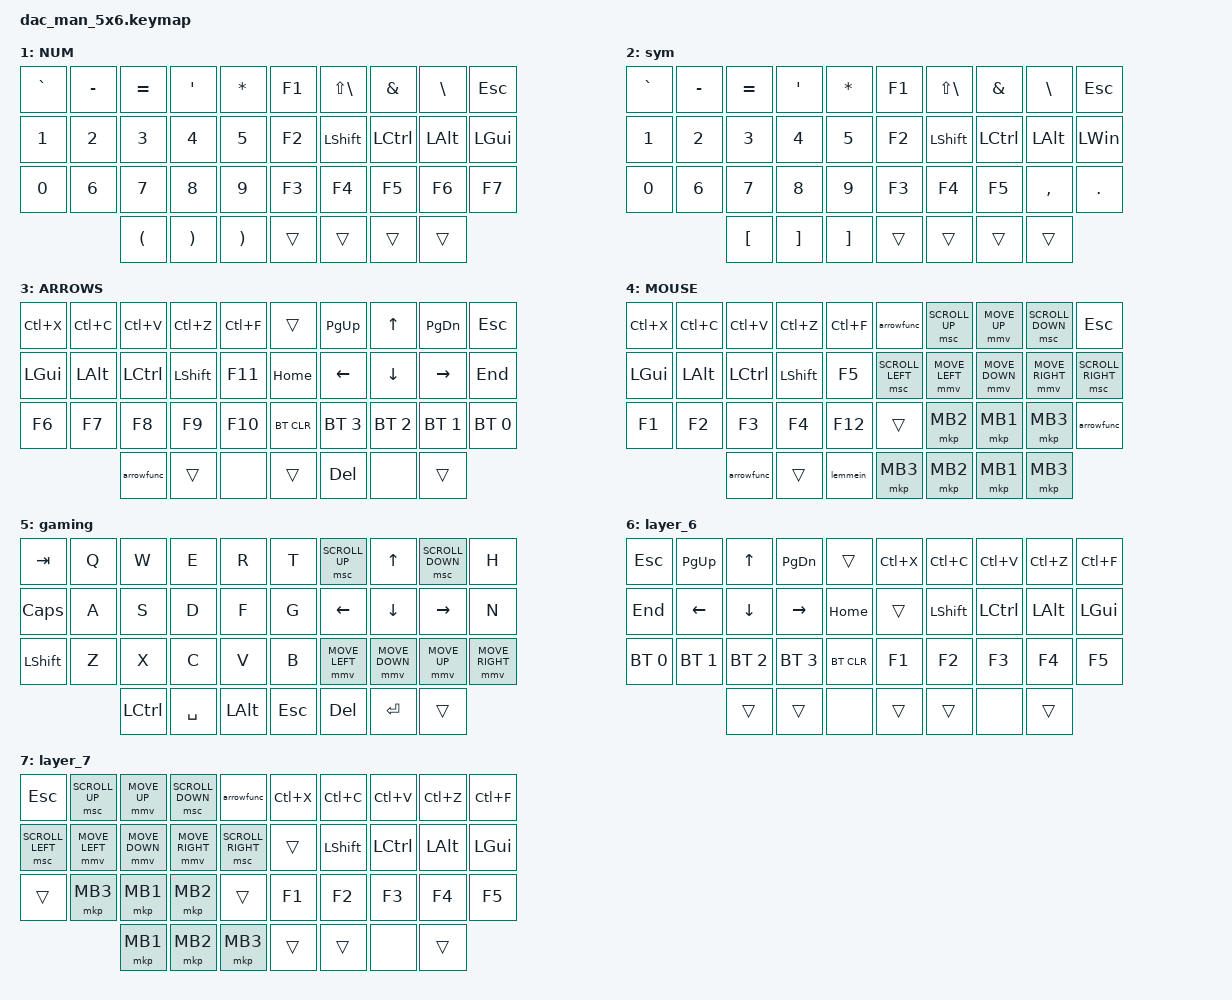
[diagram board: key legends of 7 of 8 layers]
#include <behaviors.dtsi>
#include <dt-bindings/zmk/mouse.h>
#include "mouse.dtsi"
#include <dt-bindings/zmk/bt.h>
#include <dt-bindings/zmk/keys.h>

/ {
    behaviors {
        new_behavior: new_behavior {
            compatible = "zmk,behavior-sensor-rotate";
            label = "NEW_BEHAVIOR";
            #sensor-binding-cells = <0>;
            bindings = <&msc SCROLL_DOWN>, <&msc SCROLL_UP>;
        };
    };

    combos {
        compatible = "zmk,combos";

        hotalt {
            bindings = <&mo 4>;
            key-positions = <34 35>;
        };

        hotctrl {
            bindings = <&mo 3>;
            key-positions = <33 34>;
        };

        gaming {
            bindings = <&tog 5>;
            key-positions = <33 32>;
        };

        qshift {
            bindings = <&mo 6>;
            key-positions = <32 31>;
        };

        qesc {
            bindings = <&mo 7>;
            key-positions = <31 30>;
        };

        space {
            bindings = <&kp SPACE>;
            key-positions = <11 12>;
        };

        esc {
            bindings = <&kp ESC>;
            key-positions = <1 2>;
        };

        tab {
            bindings = <&kp TAB>;
            key-positions = <22 21>;
        };

        bspace {
            bindings = <&kp BACKSPACE>;
            key-positions = <17 18>;
        };

        enter {
            bindings = <&kp ENTER>;
            key-positions = <27 28>;
        };

        del {
            bindings = <&kp DEL>;
            key-positions = <7 8>;
        };

        Lshift-0 {
            bindings = <&kp LEFT_SHIFT>;
            key-positions = <30 13>;
        };

        Lshift-1 {
            bindings = <&kp LEFT_SHIFT>;
            key-positions = <31 13>;
        };

        Rshift-0 {
            bindings = <&kp LEFT_SHIFT>;
            key-positions = <16 35>;
        };

        Rshift-1 {
            bindings = <&kp LEFT_SHIFT>;
            key-positions = <34 16>;
        };

        Lctrl_0 {
            bindings = <&kp LCTRL>;
            key-positions = <30 12>;
        };

        Lctrl_1 {
            bindings = <&kp LCTRL>;
            key-positions = <31 12>;
        };

        Rctrl_0 {
            bindings = <&kp LCTRL>;
            key-positions = <17 35>;
        };

        Rctrl_1 {
            bindings = <&kp LCTRL>;
            key-positions = <17 34>;
        };

        Lalt_0 {
            bindings = <&kp LEFT_ALT>;
            key-positions = <30 11>;
        };

        Lalt_1 {
            bindings = <&kp LEFT_ALT>;
            key-positions = <11 31>;
        };

        Ralt_0 {
            bindings = <&kp LEFT_ALT>;
            key-positions = <35 18>;
        };

        Ralt_1 {
            bindings = <&kp LEFT_ALT>;
            key-positions = <18 34>;
        };

        Lgui_0 {
            bindings = <&kp LEFT_GUI>;
            key-positions = <30 10>;
        };

        Lgui_1 {
            bindings = <&kp LEFT_GUI>;
            key-positions = <10 31>;
        };

        Rgui_0 {
            bindings = <&kp LEFT_GUI>;
            key-positions = <35 19>;
        };

        Rgui_1 {
            bindings = <&kp LEFT_GUI>;
            key-positions = <19 34>;
        };
    };

    macros {
        arrowfunc: new_macro {
            compatible = "zmk,behavior-macro";
            #binding-cells = <0>;
            bindings = <&kp LPAR &kp RPAR &kp EQUAL &kp GT &kp LEFT_BRACE>;
            label = "NEW_MACRO";
        };

        lemmein: lemmein {
            compatible = "zmk,behavior-macro";
            #binding-cells = <0>;
            bindings = <&kp LS(L) &kp D &kp POUND &kp H &kp E &kp L &kp L &kp O &kp W &kp O &kp R &kp L &kp D &kp POUND &kp N2 &kp N9>;
            label = "LEMMEIN";
        };
    };

    keymap {
        compatible = "zmk,keymap";
        label = "corne-unified";

        default_layer {
            bindings = <
  &kp Q  &kp W  &kp F      &kp P        &kp B                  &kp J            &kp L            &kp U        &kp Y       &kp SEMI
  &kp A  &kp S  &kp R      &kp T        &kp G                  &kp M            &kp N            &kp E        &kp I       &kp O
  &kp Z  &kp X  &kp C      &kp D        &kp V                  &kp K            &kp H            &kp COMMA    &kp PERIOD  &kp SLASH
  &kp Z  &kp X  &kp C      &kp D        &kp V                  &kp K            &kp H            &kp COMMA    &kp PERIOD  &kp SLASH
            >;

            sensor-bindings = <&inc_dec_kp C_VOL_DN C_VOL_UP>;
        };

        NUM {
            bindings = <
  &kp GRAVE  &kp MINUS  &kp EQUAL             &kp APOS               &kp ASTRK                &kp F1  &kp LS(BACKSLASH)  &kp AMPERSAND  &kp BSLH      &kp ESC
  &kp N1     &kp N2     &kp N3                &kp N4                 &kp N5                   &kp F2  &kp LEFT_SHIFT     &kp LCTRL      &kp LEFT_ALT  &kp LEFT_GUI
  &kp N0     &kp N6     &kp N7                &kp N8                 &kp N9                   &kp F3  &kp F4             &kp F5         &kp F6        &kp F7
                        &kp LEFT_PARENTHESIS  &kp RIGHT_PARENTHESIS  &kp RIGHT_PARENTHESIS    &trans  &trans             &trans         &trans
            >;
        };

        symbol {
            label = "sym";
            bindings = <
  &kp GRAVE  &kp MINUS  &kp EQUAL         &kp APOS           &kp ASTRK            &kp F1  &kp LS(BACKSLASH)  &kp AMPERSAND  &kp BSLH      &kp ESC
  &kp N1     &kp N2     &kp N3            &kp N4             &kp N5               &kp F2  &kp LEFT_SHIFT     &kp LCTRL      &kp LEFT_ALT  &kp LEFT_WIN
  &kp N0     &kp N6     &kp N7            &kp N8             &kp N9               &kp F3  &kp F4             &kp F5         &kp COMMA     &kp DOT
                        &kp LEFT_BRACKET  &kp RIGHT_BRACKET  &kp RIGHT_BRACKET    &trans  &trans             &trans         &trans
            >;
        };

        ARROWS {
            bindings = <
  &kp LC(X)     &kp LC(C)     &kp LC(V)   &kp LC(Z)       &kp LC(F)    &trans      &kp PG_UP     &kp UP        &kp PG_DN     &kp ESC
  &kp LEFT_GUI  &kp LEFT_ALT  &kp LCTRL   &kp LEFT_SHIFT  &kp F11      &kp HOME    &kp LEFT      &kp DOWN      &kp RIGHT     &kp END
  &kp F6        &kp F7        &kp F8      &kp F9          &kp F10      &bt BT_CLR  &bt BT_SEL 3  &bt BT_SEL 2  &bt BT_SEL 1  &bt BT_SEL 0
                              &arrowfunc  &trans          &none        &trans      &kp DELETE    &none         &trans
            >;
        };

        MOUSE {
            bindings = <
  &kp LC(X)     &kp LC(C)     &kp LC(V)   &kp LC(Z)       &kp LC(F)    &arrowfunc        &msc SCROLL_UP  &mmv MOVE_UP    &msc SCROLL_DOWN  &kp ESCAPE
  &kp LEFT_GUI  &kp LEFT_ALT  &kp LCTRL   &kp LEFT_SHIFT  &kp F5       &msc SCROLL_LEFT  &mmv MOVE_LEFT  &mmv MOVE_DOWN  &mmv MOVE_RIGHT   &msc SCROLL_RIGHT
  &kp F1        &kp F2        &kp F3      &kp F4          &kp F12      &trans            &mkp MB2        &mkp MB1        &mkp MB3          &arrowfunc
                              &arrowfunc  &trans          &lemmein     &mkp MB3          &mkp MB2        &mkp MB1        &mkp MB3
            >;
        };

        gaming {
            bindings = <
  &kp TAB         &kp Q  &kp W      &kp E      &kp R           &kp T    &msc SCROLL_UP  &kp UP          &msc SCROLL_DOWN  &kp H
  &kp CAPS        &kp A  &kp S      &kp D      &kp F           &kp G    &kp LEFT        &kp DOWN        &kp RIGHT         &kp N
  &kp LEFT_SHIFT  &kp Z  &kp X      &kp C      &kp V           &kp B    &mmv MOVE_LEFT  &mmv MOVE_DOWN  &mmv MOVE_UP      &mmv MOVE_RIGHT
                         &kp LCTRL  &kp SPACE  &kp LEFT_ALT    &kp ESC  &kp DEL         &kp ENTER       &trans
            >;
        };

        layer_6 {
            bindings = <
  &kp ESCAPE    &kp PG_UP     &kp UP        &kp PG_DN     &trans        &kp LC(X)  &kp LC(C)       &kp LC(V)  &kp LC(Z)     &kp LC(F)
  &kp END       &kp LEFT      &kp DOWN      &kp RIGHT     &kp HOME      &trans     &kp LEFT_SHIFT  &kp LCTRL  &kp LEFT_ALT  &kp LEFT_GUI
  &bt BT_SEL 0  &bt BT_SEL 1  &bt BT_SEL 2  &bt BT_SEL 3  &bt BT_CLR    &kp F1     &kp F2          &kp F3     &kp F4        &kp F5
                              &trans        &trans        &none         &trans     &trans          &none      &trans
            >;
        };

        layer_7 {
            bindings = <
  &kp ESCAPE        &msc SCROLL_UP  &mmv MOVE_UP    &msc SCROLL_DOWN  &arrowfunc           &kp LC(X)  &kp LC(C)       &kp LC(V)  &kp LC(Z)     &kp LC(F)
  &msc SCROLL_LEFT  &mmv MOVE_LEFT  &mmv MOVE_DOWN  &mmv MOVE_RIGHT   &msc SCROLL_RIGHT    &trans     &kp LEFT_SHIFT  &kp LCTRL  &kp LEFT_ALT  &kp LEFT_GUI
  &trans            &mkp MB3        &mkp MB1        &mkp MB2          &trans               &kp F1     &kp F2          &kp F3     &kp F4        &kp F5
                                    &mkp MB1        &mkp MB2          &mkp MB3             &trans     &trans          &none      &trans
            >;
        };
    };
};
